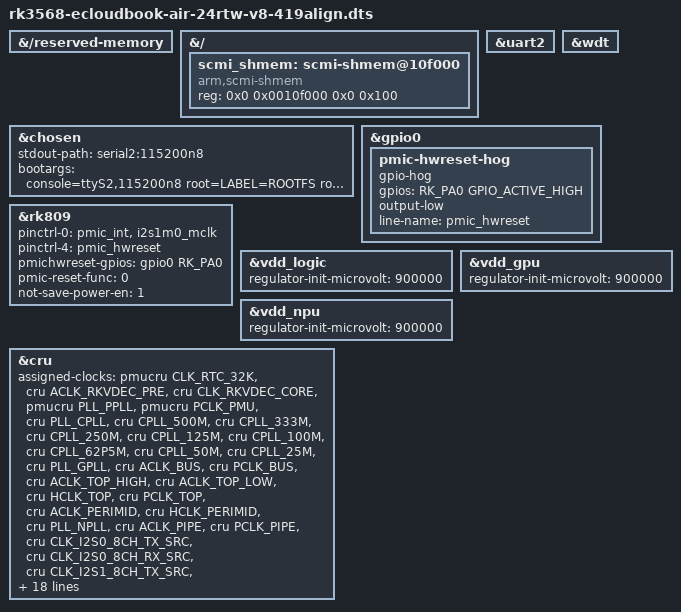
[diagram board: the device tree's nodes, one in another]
// SPDX-License-Identifier: (GPL-2.0+ OR MIT)
/*
 * Diagnostic Test 2 DTS for China Mobile (ZTE) CloudBook Air CT2000-24RTW:
 * Derives directly from v5-g3-clean (v8 baseline) with single-purpose 4.19 HW alignment:
 *  - Move scmi_shmem out of reserved-memory + disable uart2 DMA + quiet heartbeat cmdline
 *  - Remove pmic_hwreset (GPIO0_A0 pull-up) from rk809 pinctrl-0; add pinctrl-4,
 *    pmichwreset-gpios, pmic-reset-func = <0>, not-save-power-en = <1>, and gpio0 output-low hog
 *  - Align vdd_logic / vdd_gpu / vdd_npu regulator-init-microvolt = <900000>
 *  - Align &cru assigned-clocks / parents / rates to factory 4.19 DTB
 */

#include "rk3568-ecloudbook-air-24rtw-v5-g3-clean.dts"
#include <dt-bindings/clock/rk3568-cru.h>
#include <dt-bindings/gpio/gpio.h>
#include <dt-bindings/pinctrl/rockchip.h>

&{/reserved-memory} {
	/delete-node/ shmem@10f000;
};

&{/} {
	scmi_shmem: scmi-shmem@10f000 {
		compatible = "arm,scmi-shmem";
		reg = <0x0 0x0010f000 0x0 0x100>;
	};
};

&chosen {
	stdout-path = "serial2:115200n8";
	bootargs = "console=ttyS2,115200n8 root=LABEL=ROOTFS rootfstype=ext4 rootwait rw net.ifnames=0 clk_ignore_unused pd_ignore_unused cpuidle.off=1 quiet";
};

&uart2 {
	/delete-property/ dmas;
	/delete-property/ dma-names;
};

&wdt {
	status = "okay";
};

&gpio0 {
	pmic-hwreset-hog {
		gpio-hog;
		gpios = <RK_PA0 GPIO_ACTIVE_HIGH>;
		output-low;
		line-name = "pmic_hwreset";
	};
};

&rk809 {
	pinctrl-names = "default", "pmic-sleep", "pmic-power-off", "pmic-reset", "pmic-hwreset";
	pinctrl-0 = <&pmic_int>, <&i2s1m0_mclk>;
	pinctrl-4 = <&pmic_hwreset>;
	pmichwreset-gpios = <&gpio0 RK_PA0 GPIO_ACTIVE_HIGH>;
	pmic-reset-func = <0>;
	not-save-power-en = <1>;
};

&vdd_logic {
	regulator-init-microvolt = <900000>;
};

&vdd_gpu {
	regulator-init-microvolt = <900000>;
};

&vdd_npu {
	regulator-init-microvolt = <900000>;
};

&cru {
	assigned-clocks =
		<&pmucru CLK_RTC_32K>,
		<&cru ACLK_RKVDEC_PRE>,
		<&cru CLK_RKVDEC_CORE>,
		<&pmucru PLL_PPLL>,
		<&pmucru PCLK_PMU>,
		<&cru PLL_CPLL>,
		<&cru CPLL_500M>,
		<&cru CPLL_333M>,
		<&cru CPLL_250M>,
		<&cru CPLL_125M>,
		<&cru CPLL_100M>,
		<&cru CPLL_62P5M>,
		<&cru CPLL_50M>,
		<&cru CPLL_25M>,
		<&cru PLL_GPLL>,
		<&cru ACLK_BUS>,
		<&cru PCLK_BUS>,
		<&cru ACLK_TOP_HIGH>,
		<&cru ACLK_TOP_LOW>,
		<&cru HCLK_TOP>,
		<&cru PCLK_TOP>,
		<&cru ACLK_PERIMID>,
		<&cru HCLK_PERIMID>,
		<&cru PLL_NPLL>,
		<&cru ACLK_PIPE>,
		<&cru PCLK_PIPE>,
		<&cru CLK_I2S0_8CH_TX_SRC>,
		<&cru CLK_I2S0_8CH_RX_SRC>,
		<&cru CLK_I2S1_8CH_TX_SRC>,
		<&cru CLK_I2S1_8CH_RX_SRC>,
		<&cru CLK_I2S2_2CH_SRC>,
		<&cru CLK_I2S3_2CH_RX_SRC>,
		<&cru CLK_I2S3_2CH_TX_SRC>,
		<&cru MCLK_SPDIF_8CH_SRC>,
		<&cru ACLK_VOP>;
	assigned-clock-parents =
		<&pmucru CLK_RTC32K_FRAC>,
		<&cru PLL_GPLL>,
		<&cru PLL_GPLL>;
	assigned-clock-rates =
		<32768>,
		<300000000>,
		<300000000>,
		<200000000>,
		<100000000>,
		<1000000000>,
		<500000000>,
		<333000000>,
		<250000000>,
		<125000000>,
		<100000000>,
		<62500000>,
		<50000000>,
		<25000000>,
		<1188000000>,
		<150000000>,
		<100000000>,
		<500000000>,
		<400000000>,
		<150000000>,
		<100000000>,
		<300000000>,
		<150000000>,
		<1200000000>,
		<400000000>,
		<100000000>,
		<1188000000>,
		<1188000000>,
		<1188000000>,
		<1188000000>,
		<1188000000>,
		<1188000000>,
		<1188000000>,
		<1188000000>,
		<500000000>;
};
